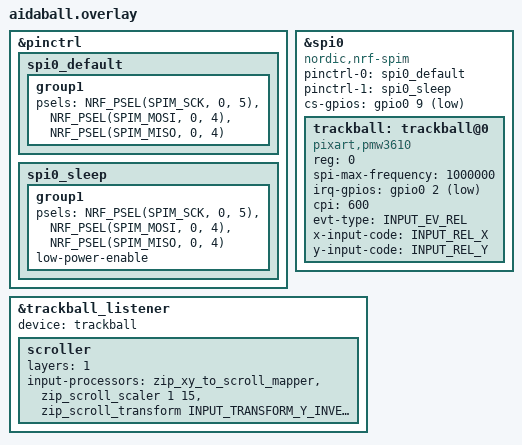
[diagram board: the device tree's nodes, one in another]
#include "aidaball.dtsi"
#include <input/processors.dtsi>

&pinctrl {
    spi0_default: spi0_default {    //通常動作時
        group1 {
            psels = <NRF_PSEL(SPIM_SCK, 0, 5)>,     //P0.05(SCLK)
                    <NRF_PSEL(SPIM_MOSI, 0, 4)>,    //P0.04(SDIO(MOSI,MISO兼用))
                    <NRF_PSEL(SPIM_MISO, 0, 4)>;
        };
    };

    spi0_sleep: spi0_sleep {        //スリープ時
        group1 {
            psels = <NRF_PSEL(SPIM_SCK, 0, 5)>,
                    <NRF_PSEL(SPIM_MOSI, 0, 4)>,
                    <NRF_PSEL(SPIM_MISO, 0, 4)>;
            low-power-enable;
        };
    };
};

#include <zephyr/dt-bindings/input/input-event-codes.h>
&spi0 {
    status = "okay";
    compatible = "nordic,nrf-spim";
    pinctrl-0 = <&spi0_default>;
    pinctrl-1 = <&spi0_sleep>;
    pinctrl-names = "default", "sleep";
    cs-gpios = <&gpio0 9 GPIO_ACTIVE_LOW>;  //P0.09(CS)

    trackball: trackball@0 {
        status = "okay";
        compatible = "pixart,pmw3610";
        reg = <0>;
        spi-max-frequency = <1000000>;
        irq-gpios = <&gpio0 2 (GPIO_ACTIVE_LOW | GPIO_PULL_UP)>; //P0.02(MOTION)
        cpi = <600>;
        evt-type = <INPUT_EV_REL>;
        x-input-code = <INPUT_REL_X>;
        y-input-code = <INPUT_REL_Y>;
    };
};


// Overrides for the input listener node
&trackball_listener {
    status = "okay";
    device = <&trackball>;
    scroller {
        layers = <1>;
        input-processors = 
                <&zip_xy_to_scroll_mapper>,                         //スクロールモードに変更
                <&zip_scroll_scaler 1 15>,                          //移動量1/15
                <&zip_scroll_transform INPUT_TRANSFORM_Y_INVERT>;   //カーソル移動のY方向を反転する
    };
};


